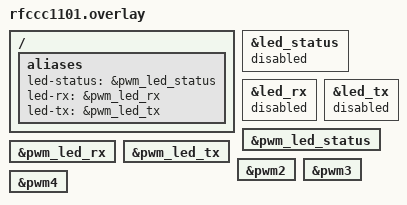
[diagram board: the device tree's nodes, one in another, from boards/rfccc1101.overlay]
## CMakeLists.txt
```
#
# SPDX-FileCopyrightText: Copyright 2024 Andreas Sandberg <andreas@sandberg.uk>
#
# SPDX-License-Identifier: Apache-2.0
#

cmake_minimum_required(VERSION 3.13.1)
find_package(Zephyr REQUIRED HINTS $ENV{ZEPHYR_BASE})

project(blinkyapp LANGUAGES C VERSION 0.1.0)

add_subdirectory(src)
```

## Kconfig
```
#
# SPDX-FileCopyrightText: Copyright 2024 Andreas Sandberg <andreas@sandberg.uk>
#
# SPDX-License-Identifier: Apache-2.0
#

mainmenu "RF Chameleon Blinky options"

menu "RF Chameleon"

module = BLINKY
module-str = RF Chameleon Blinky
source "subsys/logging/Kconfig.template.log_config"

endmenu

menu "Zephyr"
source "Kconfig.zephyr"
endmenu
```

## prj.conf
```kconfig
#
# SPDX-FileCopyrightText: Copyright 2024 Andreas Sandberg <andreas@sandberg.uk>
#
# SPDX-License-Identifier: Apache-2.0
#

CONFIG_GPIO=y
CONFIG_LED=y
CONFIG_PWM=y

CONFIG_USE_SEGGER_RTT=y

CONFIG_LOG=y
CONFIG_LOG_BACKEND_UART=y
CONFIG_LOG_BACKEND_RTT=y
CONFIG_LOG_BACKEND_RTT_BUFFER=0

CONFIG_CONSOLE=y
CONFIG_RTT_CONSOLE=y
CONFIG_UART_CONSOLE=y

CONFIG_TEST_RANDOM_GENERATOR=y
```

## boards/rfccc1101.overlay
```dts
/*
 * SPDX-FileCopyrightText: Copyright 2023-2024 Andreas Sandberg <andreas@sandberg.uk>
 *
 * SPDX-License-Identifier: Apache-2.0
 */

/ {
	aliases {
		led-status = &pwm_led_status;
		led-rx = &pwm_led_rx;
		led-tx = &pwm_led_tx;
	};
};

&led_status {
	status = "disabled";
};

&led_rx {
	status = "disabled";
};

&led_tx {
	status = "disabled";
};

&pwm_led_status {
	status = "okay";
};

&pwm_led_rx {
	status = "okay";
};

&pwm_led_tx {
	status = "okay";
};

&pwm2 {
	status = "okay";
};

&pwm3 {
	status = "okay";
};

&pwm4 {
	status = "okay";
};
```

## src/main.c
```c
/*
 * SPDX-FileCopyrightText: Copyright 2023-2024 Andreas Sandberg <andreas@sandberg.uk>
 *
 * SPDX-License-Identifier: Apache-2.0
 */

#include <zephyr/kernel.h>
#include <zephyr/logging/log.h>
#include <zephyr/drivers/led.h>
#include <zephyr/random/random.h>

LOG_MODULE_REGISTER(main, CONFIG_BLINKY_LOG_LEVEL);

enum board_led_color {
	BOARD_LED_COLOR_MONO = 0,

	BOARD_LED_COLOR_RED = BOARD_LED_COLOR_MONO,
	BOARD_LED_COLOR_GREEN,
	BOARD_LED_COLOR_BLUE,

	BOARD_LED_COLOR_MAX = BOARD_LED_COLOR_BLUE,
};

struct board_led {
	const struct device *dev;
	int colors;
	uint8_t rate;
	uint8_t state;
};

#define TICK_MS 50

static struct board_led board_leds[] = {
	{
		.dev = DEVICE_DT_GET(DT_ALIAS(led_status)),
		.rate = 255,
	},
	{
		.dev = DEVICE_DT_GET(DT_ALIAS(led_rx)),
		.rate = 48,
	},
	{
		.dev = DEVICE_DT_GET(DT_ALIAS(led_tx)),
		.rate = 4,
	},
};

static uint8_t board_led_brightness = 5;

static int board_init_led(struct board_led *led)
{
	if (!device_is_ready(led->dev)) {
		return -ENODEV;
	}

	for (uint32_t i = 0; i <= BOARD_LED_COLOR_MAX; i++) {
		if (led_off(led->dev, i) != 0) {
			led->colors = i;
			return led->colors;
		}
	}
	led->colors = BOARD_LED_COLOR_MAX + 1;
	return led->colors;
}

static void board_led_on(const struct board_led *led, enum board_led_color color)
{
	if (color >= led->colors)
		return;

	led_set_brightness(led->dev, color, board_led_brightness);
}

static void board_led_off(const struct board_led *led)
{
	for (uint32_t i = 0; i <= led->colors; i++) {
		led_off(led->dev, i);
	}
}

static void board_led_next_state(struct board_led *led)
{
	const uint32_t num = sys_rand32_get();
	const enum board_led_color color = (num & 0x0f) % led->colors;
	const uint8_t rate = (num >> 8) & 0xff;

	board_led_off(led);
	if (!led->state && rate <= led->rate) {
		board_led_on(led, color);
		led->state = 1;
	} else {
		led->state = 0;
	}
}

int main()
{
	LOG_INF("RF Chameleon Blinky");

	for (int i = 0; i < ARRAY_SIZE(board_leds); i++) {
		if (board_init_led(&board_leds[i]) < 0) {
			LOG_WRN("LED %i not ready.", i);
		}
	}

	while (1) {
		for (int i = 0; i < ARRAY_SIZE(board_leds); i++) {
			board_led_next_state(&board_leds[i]);
		}
		k_sleep(K_MSEC(TICK_MS));
	};

	return 0;
}
```
